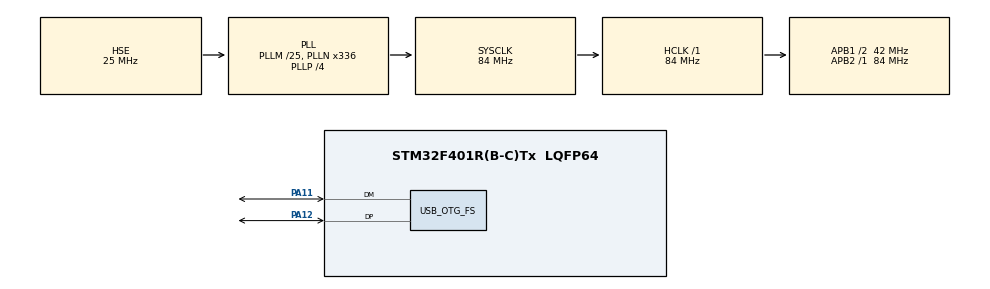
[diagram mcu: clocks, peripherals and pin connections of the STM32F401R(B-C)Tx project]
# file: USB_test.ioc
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Mcu.Family=STM32F4
Mcu.Name=STM32F401R(B-C)Tx
Mcu.Package=LQFP64
NVIC.OTG_FS_IRQn=true\:0\:0\:false\:false\:true\:false\:true\:true
NVIC.PriorityGroup=NVIC_PRIORITYGROUP_4
PA11.Mode=Device_Only
PA11.Signal=USB_OTG_FS_DM
PA12.Mode=Device_Only
PA12.Signal=USB_OTG_FS_DP
PH0\ -\ OSC_IN.Mode=HSE-External-Oscillator
PH0\ -\ OSC_IN.Signal=RCC_OSC_IN
PH1\ -\ OSC_OUT.Mode=HSE-External-Oscillator
PH1\ -\ OSC_OUT.Signal=RCC_OSC_OUT
ProjectManager.HeapSize=0x200
ProjectManager.StackSize=0x400
ProjectManager.TargetToolchain=STM32CubeIDE
RCC.48MHZClocksFreq_Value=48000000
RCC.AHBFreq_Value=84000000
RCC.APB1CLKDivider=RCC_HCLK_DIV2
RCC.APB1Freq_Value=42000000
RCC.APB1TimFreq_Value=84000000
RCC.APB2Freq_Value=84000000
RCC.APB2TimFreq_Value=84000000
RCC.CortexFreq_Value=84000000
RCC.HCLKFreq_Value=84000000
RCC.HSE_VALUE=25000000
RCC.HSI_VALUE=16000000
RCC.LSE_VALUE=32768
RCC.PLLM=25
RCC.PLLN=336
RCC.PLLP=RCC_PLLP_DIV4
RCC.PLLQ=7
RCC.SYSCLKFreq_VALUE=84000000
RCC.SYSCLKSource=RCC_SYSCLKSOURCE_PLLCLK
RCC.VCOOutputFreq_Value=336000000
USB_DEVICE.CLASS_NAME_FS=CDC
USB_DEVICE.VirtualMode=Cdc
USB_DEVICE.VirtualModeFS=Cdc_FS
USB_OTG_FS.VirtualMode=Device_Only
VP_USB_DEVICE_VS_USB_DEVICE_CDC_FS.Mode=CDC_FS
board=custom

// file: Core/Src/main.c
/* USER CODE BEGIN Header */
/**
  ******************************************************************************
  * @file           : main.c
  * @brief          : Main program body
  ******************************************************************************
  * @attention
  *
  * Copyright (c) 2024 STMicroelectronics.
  * All rights reserved.
  *
  * This software is licensed under terms that can be found in the LICENSE file
  * in the root directory of this software component.
  * If no LICENSE file comes with this software, it is provided AS-IS.
  *
  ******************************************************************************
  */
/* USER CODE END Header */
#include "main.h"
#include "usb_device.h"

/* USER CODE BEGIN PV */
uint8_t Buffer1[64];
uint8_t Buffer2[64];
uint8_t Buffer3[128];
uint8_t id[16];
uint8_t value1[16];
uint8_t value2[16];
uint8_t set=0;
uint8_t size=0;
uint8_t idx=14;
uint8_t nxt=0;
uint8_t j=0;
//uint8_t buffer1[128];
/* USER CODE END PV */

void SystemClock_Config(void);
static void MX_GPIO_Init(void);
/* USER CODE BEGIN PFP */
void USBRxHandler(uint8_t* buf,uint16_t len);
void Buffer_operation_strich(uint8_t *buf3,uint8_t *buf2,uint8_t *buf1);
uint8_t Buffer_trim_size(uint8_t *buf);
void filter_bytestream(uint8_t *buf);
void byte_stream_operation(uint8_t* buf);
/* USER CODE END PFP */

/* USER CODE BEGIN 0 */
void USBRxHandler(uint8_t* buf,uint16_t len){
	switch(set)
	{
	case(0):
			memset(Buffer1,0,64);
			memset(Buffer2,0,64);
			memcpy(Buffer1,buf,len);
			memset(buf,0,len);
			if(Buffer1[3]<=53)
			{
				Buffer_operation_strich(Buffer3,Buffer2,Buffer1);
				size=Buffer_trim_size(Buffer3);
				byte_stream_operation(Buffer3);
				set=0;
				return;

			}
			set++;
			return;
	case(1):
			memset(Buffer2,0,64);
			memcpy(Buffer2,buf,len);
			memset(buf,0,len);
			memset(Buffer3,0,64);
			Buffer_operation_strich(Buffer3,Buffer2,Buffer1);
			size=Buffer_trim_size(Buffer3);
			byte_stream_operation(Buffer3);
			set=0;
			return;
	}
	return;
}
void Buffer_operation_strich(uint8_t *buf3,uint8_t *buf2,uint8_t *buf1)
{
	for(uint8_t i=0;i<64;i++)
	{
		buf3[i]=buf1[i];
	}
	for(uint8_t i=0;i<64;i++)
	{
		buf3[64+i]=buf2[i];
	}
}
uint8_t Buffer_trim_size(uint8_t *buf)
{
	for(j=0;j<128;j++)
	{
		if (buf[j]=='.')
		{
			break;
		}
	}
	return j-1;
}
void filter_bytestream(uint8_t *buf)
{
	memset(id,0,16);
	memset(value1,0,16);
	memset(value2,0,16);
	while(idx<size)
	{
			id[nxt]=buf[idx+1];
			value1[nxt]=buf[idx+3];
			value2[nxt]=buf[idx+5];
			idx+=8;
			nxt++;
	}
}
void byte_stream_operation(uint8_t* buf)
{
	filter_bytestream(buf);
	nxt=0;
	idx=14;
	j=0;
}

/* USER CODE END 0 */

int main(void)
{

  /* MCU Configuration--------------------------------------------------------*/

  /* Reset of all peripherals, Initializes the Flash interface and the Systick. */
  HAL_Init();

  /* Configure the system clock */
  SystemClock_Config();

  /* Initialize all configured peripherals */
  MX_GPIO_Init();
  MX_USB_DEVICE_Init();
  /* Infinite loop */
  while (1)
  {
	  HAL_Delay(10);
  }
}

void SystemClock_Config(void)
{
  RCC_OscInitTypeDef RCC_OscInitStruct = {0};
  RCC_ClkInitTypeDef RCC_ClkInitStruct = {0};

  /** Configure the main internal regulator output voltage
  */
  __HAL_RCC_PWR_CLK_ENABLE();
  __HAL_PWR_VOLTAGESCALING_CONFIG(PWR_REGULATOR_VOLTAGE_SCALE2);

  /** Initializes the RCC Oscillators according to the specified parameters
  * in the RCC_OscInitTypeDef structure.
  */
  RCC_OscInitStruct.OscillatorType = RCC_OSCILLATORTYPE_HSE;
  RCC_OscInitStruct.HSEState = RCC_HSE_ON;
  RCC_OscInitStruct.PLL.PLLState = RCC_PLL_ON;
  RCC_OscInitStruct.PLL.PLLSource = RCC_PLLSOURCE_HSE;
  RCC_OscInitStruct.PLL.PLLM = 25;
  RCC_OscInitStruct.PLL.PLLN = 336;
  RCC_OscInitStruct.PLL.PLLP = RCC_PLLP_DIV4;
  RCC_OscInitStruct.PLL.PLLQ = 7;
  if (HAL_RCC_OscConfig(&RCC_OscInitStruct) != HAL_OK)
  {
    Error_Handler();
  }

  /** Initializes the CPU, AHB and APB buses clocks
  */
  RCC_ClkInitStruct.ClockType = RCC_CLOCKTYPE_HCLK|RCC_CLOCKTYPE_SYSCLK
                              |RCC_CLOCKTYPE_PCLK1|RCC_CLOCKTYPE_PCLK2;
  RCC_ClkInitStruct.SYSCLKSource = RCC_SYSCLKSOURCE_PLLCLK;
  RCC_ClkInitStruct.AHBCLKDivider = RCC_SYSCLK_DIV1;
  RCC_ClkInitStruct.APB1CLKDivider = RCC_HCLK_DIV2;
  RCC_ClkInitStruct.APB2CLKDivider = RCC_HCLK_DIV1;

  if (HAL_RCC_ClockConfig(&RCC_ClkInitStruct, FLASH_LATENCY_2) != HAL_OK)
  {
    Error_Handler();
  }
}

static void MX_GPIO_Init(void)
{

  /* GPIO Ports Clock Enable */
  __HAL_RCC_GPIOH_CLK_ENABLE();
  __HAL_RCC_GPIOA_CLK_ENABLE();

}

void Error_Handler(void)
{
  __disable_irq();
  while (1)
  {
  }
}
